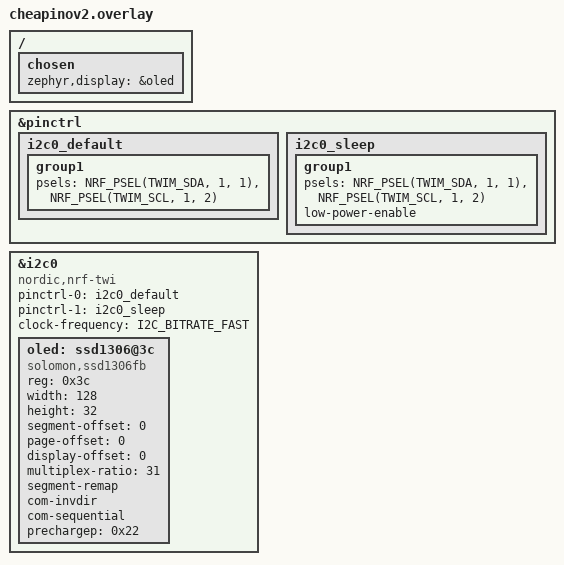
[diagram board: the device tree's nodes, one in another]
#include "cheapinov2.dtsi"
#include <zephyr/dt-bindings/i2c/i2c.h>

/* I2C0 on P1.01 (SDA) + P1.02 (SCL) - the extra THT pins on the
 * Nologo/ICBbuy Supermini nRF52840 clone. SSD1306 OLED 128x32 at 0x3C.
 */
&pinctrl {
    i2c0_default: i2c0_default {
        group1 {
            psels = <NRF_PSEL(TWIM_SDA, 1, 1)>,
                    <NRF_PSEL(TWIM_SCL, 1, 2)>;
        };
    };

    i2c0_sleep: i2c0_sleep {
        group1 {
            psels = <NRF_PSEL(TWIM_SDA, 1, 1)>,
                    <NRF_PSEL(TWIM_SCL, 1, 2)>;
            low-power-enable;
        };
    };
};

&i2c0 {
    compatible = "nordic,nrf-twi";
    status = "okay";
    pinctrl-0 = <&i2c0_default>;
    pinctrl-1 = <&i2c0_sleep>;
    pinctrl-names = "default", "sleep";
    clock-frequency = <I2C_BITRATE_FAST>;

    oled: ssd1306@3c {
        compatible = "solomon,ssd1306fb";
        reg = <0x3c>;
        width = <128>;
        height = <32>;
        segment-offset = <0>;
        page-offset = <0>;
        display-offset = <0>;
        multiplex-ratio = <31>;
        segment-remap;
        com-invdir;
        com-sequential;
        prechargep = <0x22>;
    };
};

/ {
    chosen {
        zephyr,display = &oled;
    };
};
